# STM32MP151x register map
File version: 1.0
Registers are 32-bit, read-write, reset 0x0 unless marked. A register's access mark holds for its fields unless they carry their own. Offsets are from the block's base; [hi:lo] are bit positions.

## TIM13
Base 0x40007000
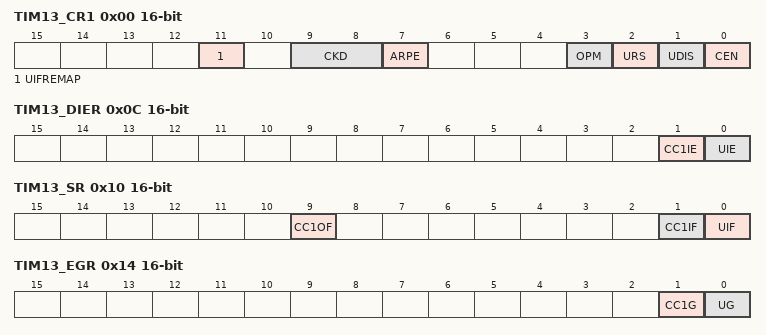
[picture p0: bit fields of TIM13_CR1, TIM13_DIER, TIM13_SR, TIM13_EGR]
0x00 TIM13_CR1 16-bit — TIM13 control register 1
  [11] UIFREMAP, [9:8] CKD, [7] ARPE, [3] OPM, [2] URS, [1] UDIS, [0] CEN
0x0C TIM13_DIER 16-bit — TIM13 Interrupt enable register
  [1] CC1IE, [0] UIE
0x10 TIM13_SR 16-bit — TIM13 status register
  [9] CC1OF, [1] CC1IF, [0] UIF
0x14 TIM13_EGR 16-bit wo — TIM13 event generation register
  [1] CC1G, [0] UG
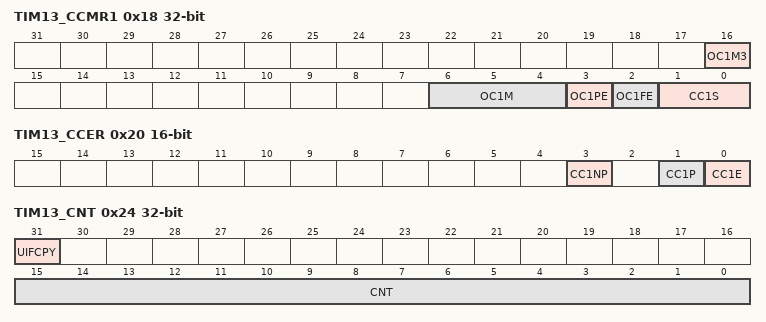
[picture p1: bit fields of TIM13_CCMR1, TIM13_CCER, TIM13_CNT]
0x18 TIM13_CCMR1 — The channels can be used in input (capture mode) or in output (compare mode). The direction of a channel is defined by configuring the corresponding CCxS bits. All the other bits of this register have a different function in input and in output mode. For a given bit, OCxx describes its function when the channel is configured in output, ICxx describes its function when the channel is configured in input. So one must take care that the same bit can have a different meaning for the input stage and for the output stage. Output compare mode
  [16] OC1M3, [6:4] OC1M, [3] OC1PE, [2] OC1FE, [1:0] CC1S
0x20 TIM13_CCER 16-bit — TIM13 capture/compare enable register
  [3] CC1NP, [1] CC1P, [0] CC1E
0x24 TIM13_CNT — TIM13 counter
  [31] UIFCPY, [15:0] CNT
0x28 TIM13_PSC 16-bit — TIM13 prescaler
0x2C TIM13_ARR 16-bit reset 0xFFFF — TIM13 auto-reload register
0x34 TIM13_CCR1 16-bit — TIM13 capture/compare register 1
0x68 TIM13_TISEL 16-bit — TIM13 timer input selection register
  [3:0] TI1SEL

## TIM14
Base 0x40008000
Registers as TIM13 (with TIM13 read as TIM14).

## I2C2
Base 0x40013000
Same registers: I2C1 0x40012000, I2C3 0x40014000, I2C5 0x40015000, I2C4 0x5C002000, I2C6 0x5C009000
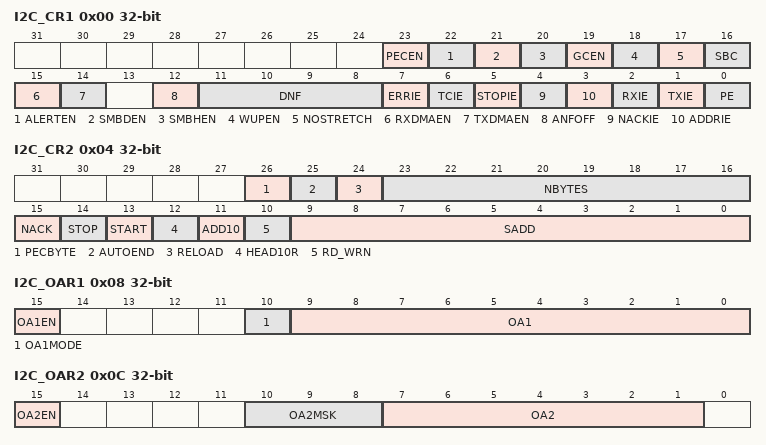
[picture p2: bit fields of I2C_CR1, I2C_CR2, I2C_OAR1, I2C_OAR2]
0x00 I2C_CR1 — Access: No wait states, except if a write access occurs while a write access to this register is ongoing. In this case, wait states are inserted in the second write access until the previous one is completed. The latency of the second write access can be up to 2xi2c_pclk+6xi2c_ker_ck.
  [23] PECEN, [22] ALERTEN, [21] SMBDEN, [20] SMBHEN, [19] GCEN, [18] WUPEN, [17] NOSTRETCH, [16] SBC, [15] RXDMAEN, [14] TXDMAEN, [12] ANFOFF, [11:8] DNF, [7] ERRIE, [6] TCIE, [5] STOPIE, [4] NACKIE, [3] ADDRIE, [2] RXIE, [1] TXIE, [0] PE
0x04 I2C_CR2 — Access: No wait states, except if a write access occurs while a write access to this register is ongoing. In this case, wait states are inserted in the second write access until the previous one is completed. The latency of the second write access can be up to 2 x i2c_pclk + 6 x i2c_ker_ck.
  [26] PECBYTE, [25] AUTOEND, [24] RELOAD, [23:16] NBYTES, [15] NACK, [14] STOP, [13] START, [12] HEAD10R, [11] ADD10, [10] RD_WRN, [9:0] SADD
0x08 I2C_OAR1 — Access: No wait states, except if a write access occurs while a write access to this register is ongoing. In this case, wait states are inserted in the second write access until the previous one is completed. The latency of the second write access can be up to 2 x i2c_pclk + 6 x i2c_ker_ck.
  [15] OA1EN, [10] OA1MODE, [9:0] OA1
0x0C I2C_OAR2 — Access: No wait states, except if a write access occurs while a write access to this register is ongoing. In this case, wait states are inserted in the second write access until the previous one is completed. The latency of the second write access can be up to 2 x i2c_pclk + 6 x i2c_ker_ck.
  [15] OA2EN, [10:8] OA2MSK, [7:1] OA2
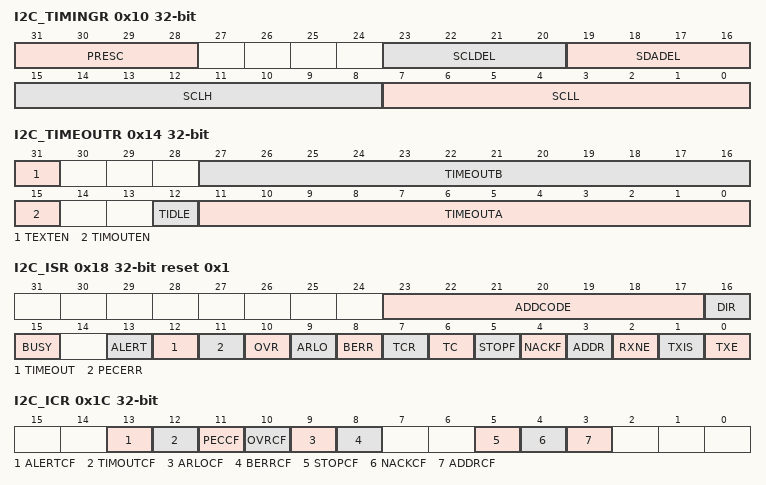
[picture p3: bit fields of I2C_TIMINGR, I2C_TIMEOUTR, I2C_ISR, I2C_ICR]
0x10 I2C_TIMINGR — Access: No wait states
  [31:28] PRESC, [23:20] SCLDEL, [19:16] SDADEL, [15:8] SCLH, [7:0] SCLL
0x14 I2C_TIMEOUTR — Access: No wait states, except if a write access occurs while a write access to this register is ongoing. In this case, wait states are inserted in the second write access until the previous one is completed. The latency of the second write access can be up to 2 x i2c_pclk + 6 x i2c_ker_ck.
  [31] TEXTEN, [27:16] TIMEOUTB, [15] TIMOUTEN, [12] TIDLE, [11:0] TIMEOUTA
0x18 I2C_ISR access per field reset 0x1 — Access: No wait states
  [23:17] ADDCODE ro, [16] DIR ro, [15] BUSY ro, [13] ALERT ro, [12] TIMEOUT ro, [11] PECERR ro, [10] OVR ro, [9] ARLO ro, [8] BERR ro, [7] TCR ro, [6] TC ro, [5] STOPF ro, [4] NACKF ro, [3] ADDR ro, [2] RXNE ro, [1] TXIS rw, [0] TXE rw
0x1C I2C_ICR wo — Access: No wait states
  [13] ALERTCF, [12] TIMOUTCF, [11] PECCF, [10] OVRCF, [9] ARLOCF, [8] BERRCF, [5] STOPCF, [4] NACKCF, [3] ADDRCF
0x20 I2C_PECR ro — Access: No wait states
  [7:0] PEC
0x24 I2C_RXDR ro — Access: No wait states
  [7:0] RXDATA
0x28 I2C_TXDR — Access: No wait states
  [7:0] TXDATA
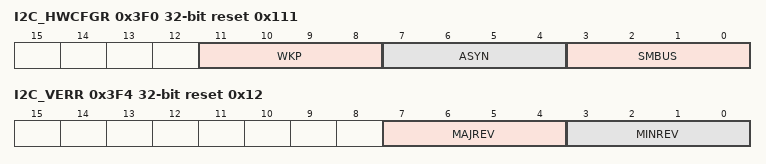
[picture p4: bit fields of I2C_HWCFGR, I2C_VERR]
0x3F0 I2C_HWCFGR ro reset 0x111 — I2C hardware configuration register
  [11:8] WKP, [7:4] ASYN, [3:0] SMBUS
0x3F4 I2C_VERR ro reset 0x12 — I2C version register
  [7:4] MAJREV, [3:0] MINREV
0x3F8 I2C_IPIDR ro reset 0x130012 — I2C identification register
  [31:0] ID
0x3FC I2C_SIDR ro reset 0xA3C5DD01 — I2C size identification register
  [31:0] SID
